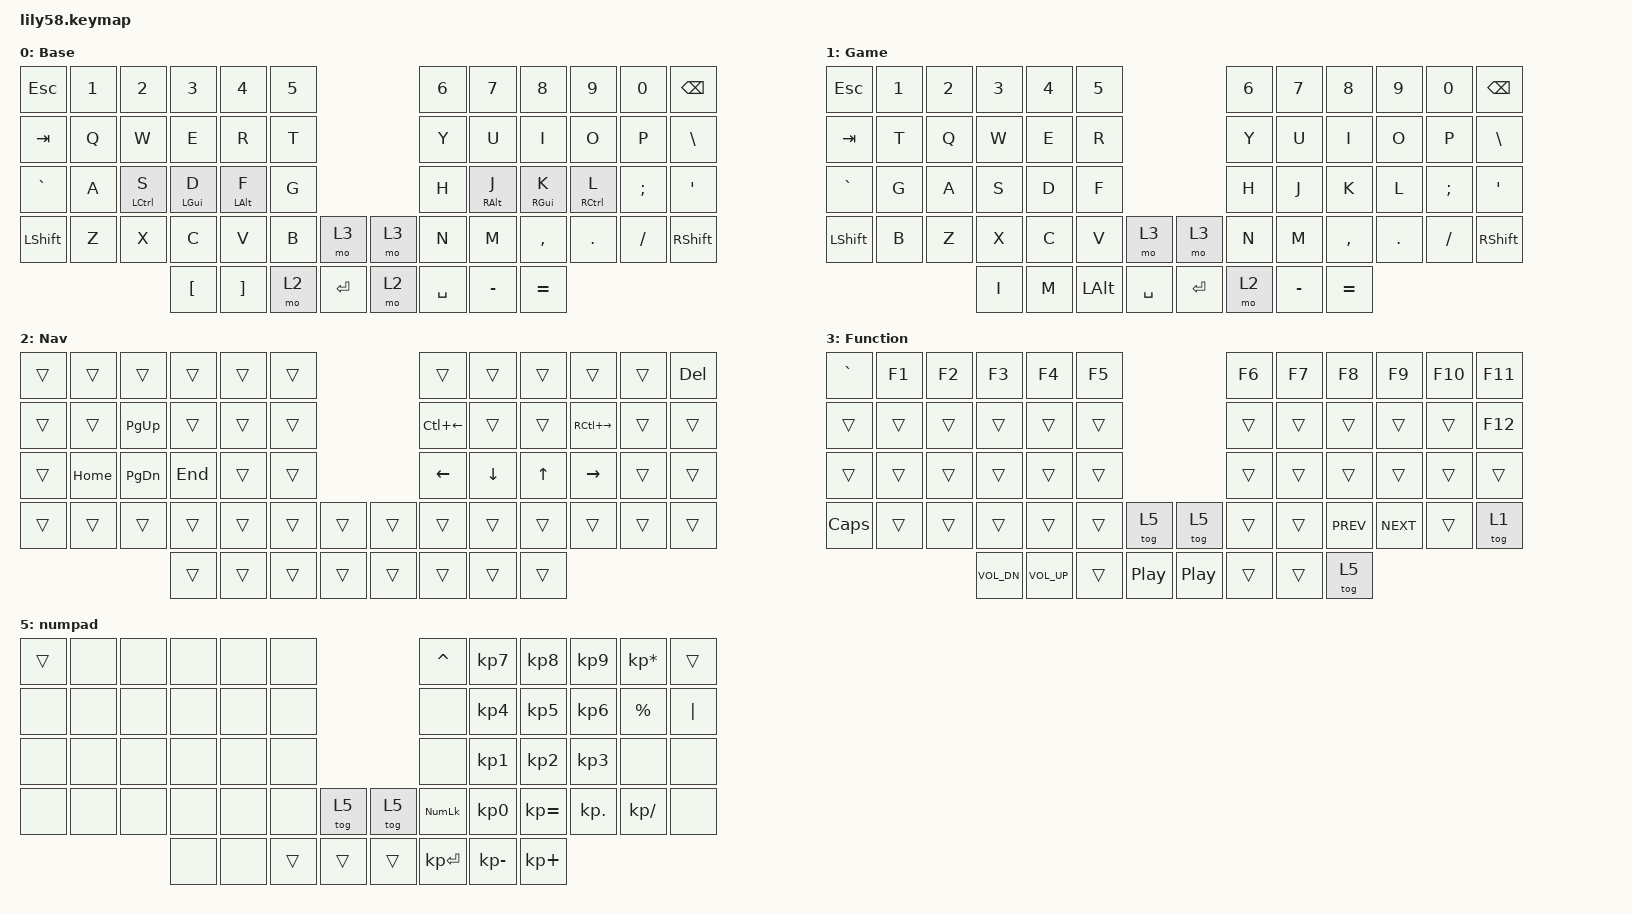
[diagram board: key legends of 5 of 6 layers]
/*
 * Copyright (c) 2020 The ZMK Contributors
 *
 * SPDX-License-Identifier: MIT
 */

#include <behaviors.dtsi>
#include <dt-bindings/zmk/keys.h>
#include <dt-bindings/zmk/bt.h>
#include <dt-bindings/zmk/ext_power.h>

/ {

    conditional_layers {
        compatible = "zmk,conditional-layers";
        tri_layer {
            if-layers = <2 3>;
            then-layer = <4>;
        };
    };

    keymap {
        compatible = "zmk,keymap";

        default_layer { // 0
            display-name = "Base";
            bindings = <
&kp ESC   &kp N1 &kp N2       &kp N3        &kp N4        &kp N5                             &kp N6 &kp N7        &kp N8         &kp N9        &kp N0   &kp BSPC
&kp TAB   &kp Q  &kp W        &kp E         &kp R         &kp T                              &kp Y  &kp U         &kp I          &kp O         &kp P    &kp BSLH
&kp GRAVE &kp A  &mt LCTRL S  &mt LGUI D    &mt LALT F    &kp G                              &kp H  &mt RALT J    &mt RGUI K     &mt RCTRL L   &kp SEMI &kp SQT
&kp LSHFT &kp Z  &kp X        &kp C         &kp V         &kp B  &mo 3          &mo 3        &kp N  &kp M         &kp COMMA      &kp DOT       &kp FSLH &kp RSHFT
                              &kp LBKT      &kp RBKT      &mo 2  &kp RET        &mo 2    &kp SPACE  &kp MINUS     &kp EQUAL
            >;
        };


         game_layer { // 1
            display-name = "Game";
            bindings = <
&kp ESC   &kp N1 &kp N2 &kp N3     &kp N4      &kp N5                             &kp N6 &kp N7    &kp N8    &kp N9  &kp N0   &kp BSPC
&kp TAB   &kp T  &kp Q  &kp W      &kp E       &kp R                              &kp Y  &kp U     &kp I     &kp O   &kp P    &kp BSLH
&kp GRAVE &kp G  &kp A  &kp S      &kp D       &kp F                              &kp H  &kp J     &kp K     &kp L   &kp SEMI &kp SQT
&kp LSHFT &kp B  &kp Z  &kp X      &kp C       &kp V     &mo 3         &mo 3      &kp N  &kp M     &kp COMMA &kp DOT &kp FSLH &kp RSHFT
                        &kp I      &kp M       &kp LALT  &kp SPACE     &kp RET    &mo 2  &kp MINUS &kp EQUAL
            >;
        };


        nav_layer { // 2
            display-name = "Nav";
            bindings = <
&trans    &trans    &trans    &trans    &trans    &trans                          &trans    &trans    &trans    &trans    &trans    &kp DEL
&trans    &trans    &kp PG_UP &trans    &trans    &trans                          &kp LC(LEFT) &trans &trans    &kp RC(RIGHT) &trans &trans
&trans    &kp HOME  &kp PG_DN &kp END   &trans    &trans                          &kp LEFT  &kp DOWN  &kp UP    &kp RIGHT &trans    &trans
&trans    &trans    &trans    &trans    &trans    &trans    &trans      &trans    &trans    &trans    &trans    &trans    &trans    &trans
                              &trans    &trans    &trans    &trans      &trans    &trans    &trans    &trans
            >;
        };


         func_layer { // 3
            display-name = "Function";
            bindings = <
&kp GRAVE &kp F1    &kp F2    &kp F3    &kp F4    &kp F5                          &kp F6    &kp F7    &kp F8    &kp F9    &kp F10   &kp F11
&trans    &trans    &trans    &trans    &trans    &trans                          &trans    &trans    &trans    &trans    &trans    &kp F12 
&trans    &trans    &trans    &trans    &trans    &trans                          &trans    &trans    &trans    &trans    &trans    &trans
&kp CAPS  &trans    &trans    &trans    &trans    &trans &tog 5            &tog 5  &trans    &trans    &kp C_PREV &kp C_NEXT &trans &tog 1
                              &kp C_VOL_DN  &kp C_VOL_UP  &trans    &kp C_PP    &kp C_PP  &trans    &trans    &tog 5
            >;
        };     


         kbcontrol_layer { // 4
            display-name = "KB Control";
            bindings = <
&bt BT_CLR &bt BT_SEL 0 &bt BT_SEL 1 &bt BT_SEL 2 &bt BT_SEL 3 &bt BT_SEL 4       &trans    &trans    &trans    &trans    &trans    &ext_power EP_OFF
&trans    &trans    &trans    &trans    &trans    &trans                          &trans    &trans    &trans    &trans    &trans    &trans
&trans    &trans    &trans    &trans    &trans    &trans                          &trans    &trans    &trans    &trans    &trans    &trans
&trans    &trans    &trans    &trans    &trans    &trans                          &trans    &trans    &trans    &trans    &trans    &ext_power EP_ON
                              &trans    &trans    &trans    &trans      &trans    &trans    &trans    &trans
            >;
        }; 


         numpad_layer { // 5
            display-name = "numpad";
            bindings = <
&trans    &none     &none     &none     &none     &none                            &kp CARET &kp KP_N7 &kp KP_N8 &kp KP_N9 &kp KP_ASTERISK &trans
&none     &none     &none     &none     &none     &none                            &none     &kp KP_N4 &kp KP_N5 &kp KP_N6 &kp PRCNT &kp PIPE
&none     &none     &none     &none     &none     &none                            &none     &kp KP_N1 &kp KP_N2 &kp KP_N3 &none     &none   
&none     &none     &none     &none     &none     &none     &tog 5      &tog 5     &kp KP_NUM &kp KP_N0 &kp KP_EQUAL &kp KP_DOT &kp KP_SLASH &none
                              &none     &none     &trans    &trans      &trans     &kp KP_ENTER &kp KP_MINUS &kp KP_PLUS  
            >;
        };     

//         new_layer { // ?
//            display-name = "new";
//            bindings = <
//&trans    &trans    &trans    &trans    &trans    &trans                          &trans    &trans    &trans    &trans    &trans    &trans
//&trans    &trans    &trans    &trans    &trans    &trans                          &trans    &trans    &trans    &trans    &trans    &trans
//&trans    &trans    &trans    &trans    &trans    &trans                          &trans    &trans    &trans    &trans    &trans    &trans
//&trans    &trans    &trans    &trans    &trans    &trans    &trans      &trans    &trans    &trans    &trans    &trans    &trans    &trans
//                              &trans    &trans    &trans    &trans      &trans    &trans    &trans    &trans
//            >;
//        }; 
//&kp       &kp       &kp       &kp       &kp       &kp                             &kp       &kp       &kp       &kp       &kp       &kp   
    };


};

&mt {
    flavor = "tap-preferred";
};

